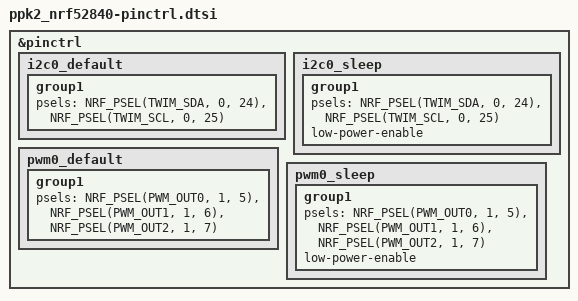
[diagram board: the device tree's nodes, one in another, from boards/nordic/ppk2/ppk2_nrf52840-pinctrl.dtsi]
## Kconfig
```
# SPDX-License-Identifier: Apache-2.0

mainmenu "Joule Counter firmware"

menu "PPK2"

config PPK2_USB_VID
	hex "USB vendor ID"
	default 0x1915
	help
	  The desktop Power Profiler app only lists devices carrying Nordic's
	  vendor ID (nrf-device-lib's "nordicUsb" trait).

config PPK2_USB_PID
	hex "USB product ID"
	default 0xC00A
	help
	  The desktop app recognises a PPK2 by idProduct == 0xC00A.

config PPK2_USB_MANUFACTURER
	string "USB manufacturer string"
	default "Nordic Semiconductor"

config PPK2_USB_PRODUCT
	string "USB product string"
	default "Joule Counter"

config PPK2_DFU_SEMVER
	string "Version string served on the DFU trigger interface"
	default "joule_counter 0.1.0"
	help
	  The app reads this string to decide whether it should offer to
	  reprogram the kit. This firmware's wire protocol has diverged from
	  the stock PPK2's (voltage stream, wider samples), so it identifies as
	  its own product rather than claiming to be a power_profiler_kit_2.
	  The default matches what Joule-Counter's DeviceSelector expects, so
	  the app leaves this firmware alone.

config PPK2_FW_VERSION_MAJOR
	int "Firmware major version reported in DFU info"
	default 1

config PPK2_FW_VERSION_MINOR
	int "Firmware minor version reported in DFU info"
	default 2

config PPK2_DEFAULT_VDD_MV
	int "Source-mode output voltage used when the EEPROM holds none (mV)"
	range 800 5000
	default 3000

config PPK2_DISCARD_SWITCH_SAMPLES
	bool "Drop samples taken while the range switches are in transition"
	default y
	help
	  The analog front end reports an inconsistent switch pattern for a few
	  microseconds while it changes range. Such samples carry no usable
	  current reading; dropping them keeps the sample counter contiguous so
	  the desktop app never sees them.

config PPK2_SAMPLE_RING_SAMPLES
	int "Sample ring buffer depth (samples, power of two)"
	default 4096
	help
	  Eight 512-sample blocks by default: enough to ride out USB scheduling
	  jitter without dropping data. 16 KiB of RAM.

config PPK2_USB_TX_INFLIGHT
	int "Sample blocks queued to the USB controller at once"
	range 1 8
	default 4

config PPK2_STREAM_KEEPS_CPU_AWAKE
	bool "Skip WFI in the idle thread while the current stream runs"
	default y
	select ARM_ON_ENTER_CPU_IDLE_HOOK
	help
	  Waking the CPU from WFI takes about 12.5 us on this kit, longer than
	  the 10 us sample period, so an idle CPU services only every other
	  conversion. With this enabled the idle thread spins instead of
	  sleeping while sampling is active. The kit is USB powered and its own
	  consumption is not what it measures, so nothing is lost.

endmenu

source "Kconfig.zephyr"
```

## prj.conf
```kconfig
# Power Profiler Kit II firmware.
#
# The board supplies the LFCLK source, the bootloader-aware flash offset and
# the USB stack selection; this file asks for what the application uses.

CONFIG_LOG=y
CONFIG_LOG_DEFAULT_LEVEL=3

# Cortex-M4F: calibration maths and voltage conversion are floating point.
CONFIG_FPU=y

# The SAADC END handler runs as a zero-latency interrupt: it has 10 us to
# collect each result and must not wait behind irq_lock() sections in the USB
# driver. It makes no kernel calls; a TIMER3 compare interrupt signals blocks.
CONFIG_ZERO_LATENCY_IRQS=y

CONFIG_GPIO=y
CONFIG_I2C=y
CONFIG_EEPROM=y
CONFIG_PWM=y
CONFIG_LED=y
CONFIG_LED_PWM=y
CONFIG_HWINFO=y
CONFIG_REBOOT=y
CONFIG_CRC=y

# The metadata reply and the shell print floats with printf-style formatting.
CONFIG_PICOLIBC_IO_FLOAT=y
CONFIG_CBPRINTF_FP_SUPPORT=y

# USB: this application builds its own composite device (data port, shell
# port, DFU trigger), so the board's boot-time CDC ACM convenience must stay
# out of the way.
CONFIG_USB_DEVICE_STACK_NEXT=y
CONFIG_USBD_CDC_ACM_CLASS=y
CONFIG_CDC_ACM_SERIAL_INITIALIZE_AT_BOOT=n
# Sample blocks are 4 KiB bulk transfers (512 two-word samples); several are
# in flight at once and the pool needs headroom beyond them for headers and
# the control/RX buffers, or allocations fail under load.
CONFIG_UDC_BUF_POOL_SIZE=32768
CONFIG_UDC_BUF_COUNT=32

CONFIG_SERIAL=y
CONFIG_CONSOLE=y
CONFIG_UART_CONSOLE=y
CONFIG_UART_LINE_CTRL=y
CONFIG_SHELL=y
CONFIG_SHELL_BACKEND_SERIAL=y
CONFIG_SHELL_BACKEND_SERIAL_CHECK_DTR=y
CONFIG_SHELL_PROMPT_UART="ppk2:~$ "

CONFIG_MAIN_STACK_SIZE=4096
CONFIG_SYSTEM_WORKQUEUE_STACK_SIZE=2048
CONFIG_HEAP_MEM_POOL_SIZE=8192
```

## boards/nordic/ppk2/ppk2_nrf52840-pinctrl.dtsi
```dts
/*
 * SPDX-License-Identifier: Apache-2.0
 */

&pinctrl {
	/* U7 (24CW160 EEPROM) and U10 (MCP4451 quad digital potentiometer)
	 * share this bus.
	 */
	i2c0_default: i2c0_default {
		group1 {
			psels = <NRF_PSEL(TWIM_SDA, 0, 24)>,
				<NRF_PSEL(TWIM_SCL, 0, 25)>;
		};
	};

	i2c0_sleep: i2c0_sleep {
		group1 {
			psels = <NRF_PSEL(TWIM_SDA, 0, 24)>,
				<NRF_PSEL(TWIM_SCL, 0, 25)>;
			low-power-enable;
		};
	};

	/* Status LED channels, through the Q15/Q1 low-side MOSFETs. */
	pwm0_default: pwm0_default {
		group1 {
			psels = <NRF_PSEL(PWM_OUT0, 1, 5)>,
				<NRF_PSEL(PWM_OUT1, 1, 6)>,
				<NRF_PSEL(PWM_OUT2, 1, 7)>;
		};
	};

	pwm0_sleep: pwm0_sleep {
		group1 {
			psels = <NRF_PSEL(PWM_OUT0, 1, 5)>,
				<NRF_PSEL(PWM_OUT1, 1, 6)>,
				<NRF_PSEL(PWM_OUT2, 1, 7)>;
			low-power-enable;
		};
	};
};
```

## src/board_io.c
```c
/*
 * Control and status lines of the PPK2 front end.
 *
 * SPDX-License-Identifier: Apache-2.0
 */

#include <zephyr/kernel.h>
#include <zephyr/device.h>
#include <zephyr/devicetree.h>
#include <zephyr/drivers/gpio.h>
#include <zephyr/logging/log.h>

#include "board_io.h"
#include "ppk2.h"

LOG_MODULE_REGISTER(board_io, CONFIG_LOG_DEFAULT_LEVEL);

#define CTRL_NODE DT_NODELABEL(ppk2_control)

static const struct gpio_dt_spec ctrl[BOARD_CTRL_COUNT] = {
	[BOARD_CTRL_VOUT_EN] = GPIO_DT_SPEC_GET(CTRL_NODE, vout_en_gpios),
	[BOARD_CTRL_VLDO_EN] = GPIO_DT_SPEC_GET(CTRL_NODE, vldo_en_gpios),
	[BOARD_CTRL_VEXT_EN] = GPIO_DT_SPEC_GET(CTRL_NODE, vext_en_gpios),
	[BOARD_CTRL_REG_EN] = GPIO_DT_SPEC_GET(CTRL_NODE, reg_en_gpios),
	[BOARD_CTRL_ANA_EN] = GPIO_DT_SPEC_GET(CTRL_NODE, ana_en_gpios),
	[BOARD_CTRL_LP_EN] = GPIO_DT_SPEC_GET(CTRL_NODE, lp_en_gpios),
};

static const struct gpio_dt_spec cal[BOARD_CAL_COUNT] = {
	GPIO_DT_SPEC_GET_BY_IDX(CTRL_NODE, cal_gpios, 0),
	GPIO_DT_SPEC_GET_BY_IDX(CTRL_NODE, cal_gpios, 1),
	GPIO_DT_SPEC_GET_BY_IDX(CTRL_NODE, cal_gpios, 2),
	GPIO_DT_SPEC_GET_BY_IDX(CTRL_NODE, cal_gpios, 3),
};

static const struct gpio_dt_spec sw[4] = {
	GPIO_DT_SPEC_GET_BY_IDX(CTRL_NODE, sw_gpios, 0),
	GPIO_DT_SPEC_GET_BY_IDX(CTRL_NODE, sw_gpios, 1),
	GPIO_DT_SPEC_GET_BY_IDX(CTRL_NODE, sw_gpios, 2),
	GPIO_DT_SPEC_GET_BY_IDX(CTRL_NODE, sw_gpios, 3),
};

static const struct gpio_dt_spec lp_data[8] = {
	GPIO_DT_SPEC_GET_BY_IDX(CTRL_NODE, lp_data_gpios, 0),
	GPIO_DT_SPEC_GET_BY_IDX(CTRL_NODE, lp_data_gpios, 1),
	GPIO_DT_SPEC_GET_BY_IDX(CTRL_NODE, lp_data_gpios, 2),
	GPIO_DT_SPEC_GET_BY_IDX(CTRL_NODE, lp_data_gpios, 3),
	GPIO_DT_SPEC_GET_BY_IDX(CTRL_NODE, lp_data_gpios, 4),
	GPIO_DT_SPEC_GET_BY_IDX(CTRL_NODE, lp_data_gpios, 5),
	GPIO_DT_SPEC_GET_BY_IDX(CTRL_NODE, lp_data_gpios, 6),
	GPIO_DT_SPEC_GET_BY_IDX(CTRL_NODE, lp_data_gpios, 7),
};

static const struct gpio_dt_spec ext_usb = GPIO_DT_SPEC_GET(CTRL_NODE, ext_usb_gpios);

/*
 * The sampling interrupt reads GPIO port registers directly rather than
 * going through the driver, so the pin numbers it assumes are pinned to the
 * devicetree here.
 */
BUILD_ASSERT(DT_GPIO_PIN_BY_IDX(CTRL_NODE, sw_gpios, 0) == 0);
BUILD_ASSERT(DT_GPIO_PIN_BY_IDX(CTRL_NODE, sw_gpios, 1) == 1);
BUILD_ASSERT(DT_GPIO_PIN_BY_IDX(CTRL_NODE, sw_gpios, 2) == 26);
BUILD_ASSERT(DT_GPIO_PIN_BY_IDX(CTRL_NODE, sw_gpios, 3) == 27);
BUILD_ASSERT(DT_GPIO_PIN_BY_IDX(CTRL_NODE, lp_data_gpios, 0) == BOARD_P0_LOGIC_SHIFT);
BUILD_ASSERT(DT_GPIO_PIN_BY_IDX(CTRL_NODE, lp_data_gpios, 7) == BOARD_P0_LOGIC_SHIFT + 7);
BUILD_ASSERT(DT_GPIO_PIN(CTRL_NODE, ext_usb_gpios) == BOARD_P1_EXT_USB_PIN);

/*
 * The comparators close the bypass switches in order as the current rises:
 * SW1 first, then SW2 on top of it, and so on. Any other pattern is a
 * snapshot taken mid-transition.
 */
static const uint8_t range_lut[16] = {
	[0x0] = 0, [0x1] = 1, [0x3] = 2, [0x7] = 3, [0xF] = 4,
	[0x2] = PPK2_RANGE_SWITCHING, [0x4] = PPK2_RANGE_SWITCHING,
	[0x5] = PPK2_RANGE_SWITCHING, [0x6] = PPK2_RANGE_SWITCHING,
	[0x8] = PPK2_RANGE_SWITCHING, [0x9] = PPK2_RANGE_SWITCHING,
	[0xA] = PPK2_RANGE_SWITCHING, [0xB] = PPK2_RANGE_SWITCHING,
	[0xC] = PPK2_RANGE_SWITCHING, [0xD] = PPK2_RANGE_SWITCHING,
	[0xE] = PPK2_RANGE_SWITCHING,
};

static int configure_all(const struct gpio_dt_spec *specs, size_t n, gpio_flags_t flags)
{
	for (size_t i = 0; i < n; i++) {
		if (!gpio_is_ready_dt(&specs[i])) {
			return -ENODEV;
		}

		int ret = gpio_pin_configure_dt(&specs[i], flags);

		if (ret < 0) {
			return ret;
		}
	}

	return 0;
}

int board_io_init(void)
{
	int ret;

	/* Everything that can put voltage on the terminals starts off. */
	ret = configure_all(ctrl, ARRAY_SIZE(ctrl), GPIO_OUTPUT_INACTIVE);
	if (ret < 0) {
		LOG_ERR("control lines: %d", ret);
		return ret;
	}

	ret = configure_all(cal, ARRAY_SIZE(cal), GPIO_OUTPUT_INACTIVE);
	if (ret < 0) {
		LOG_ERR("calibration loads: %d", ret);
		return ret;
	}

	ret = configure_all(sw, ARRAY_SIZE(sw), GPIO_INPUT);
	if (ret < 0) {
		LOG_ERR("range inputs: %d", ret);
		return ret;
	}

	ret = configure_all(lp_data, ARRAY_SIZE(lp_data), GPIO_INPUT);
	if (ret < 0) {
		LOG_ERR("logic port: %d", ret);
		return ret;
	}

	ret = gpio_pin_configure_dt(&ext_usb, GPIO_INPUT);
	if (ret < 0) {
		return ret;
	}

	/* The analog rails and the logic-port translator are always wanted. */
	board_io_set(BOARD_CTRL_ANA_EN, true);
	board_io_set(BOARD_CTRL_LP_EN, true);

	return 0;
}

int board_io_set(enum board_ctrl line, bool on)
{
	if (line >= BOARD_CTRL_COUNT) {
		return -EINVAL;
	}

	return gpio_pin_set_dt(&ctrl[line], on ? 1 : 0);
}

bool board_io_get(enum board_ctrl line)
{
	if (line >= BOARD_CTRL_COUNT) {
		return false;
	}

	return gpio_pin_get_dt(&ctrl[line]) > 0;
}

int board_io_set_cal_load(enum board_cal_load load)
{
	/* Never two loads at once: open the active one before closing another. */
	for (int i = 0; i < BOARD_CAL_COUNT; i++) {
		if (i != load) {
			gpio_pin_set_dt(&cal[i], 0);
		}
	}

	if (load >= 0 && load < BOARD_CAL_COUNT) {
		return gpio_pin_set_dt(&cal[load], 1);
	}

	return 0;
}

uint8_t board_io_decode_range(uint32_t sw_bits)
{
	return range_lut[sw_bits & 0xF];
}

uint8_t board_io_read_range(void)
{
	uint32_t bits = 0;

	for (int i = 0; i < 4; i++) {
		if (gpio_pin_get_dt(&sw[i]) > 0) {
			bits |= BIT(i);
		}
	}

	return board_io_decode_range(bits);
}

bool board_io_ext_usb_present(void)
{
	return gpio_pin_get_dt(&ext_usb) > 0;
}
```

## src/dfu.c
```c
/*
 * Hand-over to the factory nRF5 bootloader.
 *
 * The bootloader starts DFU mode when it finds BOOTLOADER_DFU_START in
 * GPREGRET after a reset. That is also what the desktop app's firmware update
 * relies on, through the DFU trigger USB interface.
 *
 * SPDX-License-Identifier: Apache-2.0
 */

#include <zephyr/kernel.h>
#include <zephyr/sys/reboot.h>
#include <zephyr/logging/log.h>

#include <nrfx.h>
#include <hal/nrf_power.h>

#include "dfu.h"

LOG_MODULE_REGISTER(dfu, CONFIG_LOG_DEFAULT_LEVEL);

#define BOOTLOADER_DFU_START	0xB1
#define NRF52840_FLASH_SIZE	(1024U * 1024U)
#define NRF52840_FLASH_PAGE	4096U

extern char __rom_region_start[];
/* Exact image size, as the linker computes it; the region end is page-rounded. */
extern char _flash_used[];

static void reboot_work_handler(struct k_work *work)
{
	ARG_UNUSED(work);

	nrf_power_gpregret_set(NRF_POWER, 0, BOOTLOADER_DFU_START);
	sys_reboot(SYS_REBOOT_COLD);
}

static K_WORK_DELAYABLE_DEFINE(reboot_work, reboot_work_handler);

void dfu_get_info(struct dfu_info *info)
{
	info->address = (uint32_t)__rom_region_start;
	info->firmware_size = (uint32_t)_flash_used;
	info->version_major = CONFIG_PPK2_FW_VERSION_MAJOR;
	info->version_minor = CONFIG_PPK2_FW_VERSION_MINOR;
	info->firmware_id = 0;
	info->flash_size = NRF52840_FLASH_SIZE;
	info->flash_page_size = NRF52840_FLASH_PAGE;
}

void dfu_enter_bootloader(void)
{
	LOG_INF("rebooting into bootloader");
	k_work_schedule(&reboot_work, K_MSEC(100));
}
```

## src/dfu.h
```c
/*
 * Hand-over to the factory nRF5 bootloader.
 *
 * SPDX-License-Identifier: Apache-2.0
 */

#ifndef DFU_H_
#define DFU_H_

#include <stdint.h>

/* Layout of the reply to the DFU trigger's DFU_INFO request. */
struct dfu_info {
	uint32_t address;
	uint32_t firmware_size;
	uint16_t version_major;
	uint16_t version_minor;
	uint32_t firmware_id;
	uint32_t flash_size;
	uint32_t flash_page_size;
} __packed;

void dfu_get_info(struct dfu_info *info);

/* Reboots into the bootloader after a short delay so USB can finish up. */
void dfu_enter_bootloader(void);

#endif /* DFU_H_ */
```

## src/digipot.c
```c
/*
 * MCP4451 quad digital potentiometer (U10).
 *
 * SPDX-License-Identifier: Apache-2.0
 */

#include <zephyr/kernel.h>
#include <zephyr/drivers/i2c.h>
#include <zephyr/logging/log.h>

#include "digipot.h"

LOG_MODULE_REGISTER(digipot, CONFIG_LOG_DEFAULT_LEVEL);

static const struct i2c_dt_spec pot = I2C_DT_SPEC_GET(DT_NODELABEL(digipot));

/* Volatile wiper register addresses, MCP4451 datasheet table 4-1. */
static const uint8_t wiper_reg[4] = { 0x00, 0x01, 0x06, 0x07 };

static uint16_t last_code[4];

int digipot_init(void)
{
	if (!i2c_is_ready_dt(&pot)) {
		LOG_ERR("I2C bus not ready");
		return -ENODEV;
	}

	return 0;
}

int digipot_set(enum digipot_wiper wiper, uint16_t code)
{
	if (wiper > DIGIPOT_IA_OFFSET) {
		return -EINVAL;
	}

	if (code > DIGIPOT_CODE_MAX) {
		code = DIGIPOT_CODE_MAX;
	}

	/* Command byte: AD3..AD0, C1 C0 = 00 (write), D9 D8. Then D7..D0. */
	const uint8_t buf[2] = {
		(uint8_t)((wiper_reg[wiper] << 4) | ((code >> 8) & 0x03)),
		(uint8_t)(code & 0xFF),
	};

	int ret = i2c_write_dt(&pot, buf, sizeof(buf));

	if (ret == 0) {
		last_code[wiper] = code;
	} else {
		LOG_WRN("wiper %d write failed: %d", wiper, ret);
	}

	return ret;
}

uint16_t digipot_get(enum digipot_wiper wiper)
{
	return wiper <= DIGIPOT_IA_OFFSET ? last_code[wiper] : 0;
}
```

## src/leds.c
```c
/*
 * Status LED patterns.
 *
 *   blue, breathing   no host connected
 *   blue, steady      host connected, idle
 *   green, breathing  streaming samples
 *   red added         DUT output is powered
 *
 * SPDX-License-Identifier: Apache-2.0
 */

#include <zephyr/kernel.h>
#include <zephyr/device.h>
#include <zephyr/drivers/led.h>
#include <zephyr/logging/log.h>

#include "leds.h"
#include "power.h"
#include "protocol.h"
#include "usb_ppk.h"

LOG_MODULE_REGISTER(leds, CONFIG_LOG_DEFAULT_LEVEL);

#define LED_RED		0
#define LED_GREEN	1
#define LED_BLUE	2

#define TICK_MS		40
#define BREATH_STEPS	50

static const struct device *const leds = DEVICE_DT_GET(DT_NODELABEL(pwmleds));
static bool ready;

static uint8_t breathe(uint32_t tick, uint8_t low, uint8_t high)
{
	uint32_t phase = tick % (2 * BREATH_STEPS);
	uint32_t up = phase < BREATH_STEPS ? phase : (2 * BREATH_STEPS - phase);

	return low + (uint8_t)((high - low) * up / BREATH_STEPS);
}

static void set_rgb(uint8_t r, uint8_t g, uint8_t b)
{
	led_set_brightness(leds, LED_RED, r);
	led_set_brightness(leds, LED_GREEN, g);
	led_set_brightness(leds, LED_BLUE, b);
}

static void led_thread(void *p1, void *p2, void *p3)
{
	uint32_t tick = 0;

	ARG_UNUSED(p1);
	ARG_UNUSED(p2);
	ARG_UNUSED(p3);

	while (!ready) {
		k_msleep(TICK_MS);
	}

	for (;;) {
		uint8_t r = power_output() ? 25 : 0;
		uint8_t g = 0;
		uint8_t b = 0;

		if (protocol_streaming()) {
			g = breathe(tick, 5, 60);
		} else if (usb_ppk_data_connected()) {
			b = 30;
		} else {
			b = breathe(tick, 2, 25);
		}

		set_rgb(r, g, b);
		tick++;
		k_msleep(TICK_MS);
	}
}

K_THREAD_DEFINE(leds_tid, 1024, led_thread, NULL, NULL, NULL, K_PRIO_PREEMPT(14), 0, 0);

int leds_init(void)
{
	if (!device_is_ready(leds)) {
		LOG_ERR("PWM LEDs not ready");
		return -ENODEV;
	}

	set_rgb(20, 20, 20);
	ready = true;

	return 0;
}
```

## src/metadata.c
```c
/*
 * Calibration metadata stored in the on-board EEPROM (U7).
 *
 * The EEPROM is the one copy of this unit's factory calibration, so writes
 * are field-wise, to offsets confirmed against the stock layout, and only
 * for values this firmware actually changes. Everything else in the stock
 * image is read and left alone.
 *
 * SPDX-License-Identifier: Apache-2.0
 */

#include <ctype.h>
#include <math.h>
#include <stdio.h>
#include <stdlib.h>
#include <string.h>

#include <zephyr/kernel.h>
#include <zephyr/device.h>
#include <zephyr/drivers/eeprom.h>
#include <zephyr/sys/byteorder.h>
#include <zephyr/sys/crc.h>
#include <zephyr/logging/log.h>

#include <nrfx.h>

#include "metadata.h"
#include "ppk2.h"
#include "sampling.h"

LOG_MODULE_REGISTER(metadata, CONFIG_LOG_DEFAULT_LEVEL);

/*
 * Our own backup lives clear of both stock regions: its primary image ends at
 * 0x100 and its backup copy (with a trailing CRC) occupies 0x600..0x702.
 */
#define BACKUP_OFFSET		0x200
#define BACKUP_MAGIC		0x324B5050	/* "PPK2" */
#define SAVE_DEBOUNCE		K_SECONDS(2)

#define IA_DEFAULT		128
#define IA_MAX			256

/*
 * Stock masks the range-0 gain terms when it reports them, whatever the
 * EEPROM holds (a real unit stored GS0 = -1138.7, GI0 = 1.03 and reported
 * 1e-19 and 1.0). The epsilon rather than zero matters: the desktop app
 * substitutes its own default of 1.0 for any value that parses as zero.
 */
#define REPORTED_GS0		1e-19f
#define REPORTED_GI0		1.0f

struct backup_image {
	uint32_t magic;
	struct ppk2_metadata meta;
	uint32_t crc;
} __packed;

static const struct device *const eeprom = DEVICE_DT_GET(DT_ALIAS(eeprom_0));

static struct ppk2_metadata meta;
/* What the EEPROM holds for the fields we own, so saves touch only changes. */
static struct ppk2_metadata stored;
static bool calibrated;
static bool ia_unknown;
static K_MUTEX_DEFINE(lock);

/*
 * Mirrors the desktop app's own fallbacks, which it substitutes for any key
 * that parses as zero. Sending anything else for an uncalibrated kit would
 * therefore be overridden anyway.
 */
static const struct ppk2_metadata defaults = {
	.r = { 1031.64f, 101.65f, 10.15f, 0.94f, 0.043f },
	.gs = { 1.0f, 1.0f, 1.0f, 1.0f, 1.0f },
	.gi = { 1.0f, 1.0f, 1.0f, 1.0f, 1.0f },
	.ug = { 1.0f, 1.0f, 1.0f, 1.0f, 1.0f },
	.vdd = CONFIG_PPK2_DEFAULT_VDD_MV,
	.mode = PPK2_MODE_AMPERE,
	.calibrated = 0,
	.ia = IA_DEFAULT,
};

static uint16_t derived_hw(void)
{
	/* Stock reports the low 16 bits of DEVICEID[0] as a decimal integer;
	 * a real unit confirmed the field and its width.
	 */
	return (uint16_t)(NRF_FICR->DEVICEID[0] & 0xFFFFU);
}

static bool all_finite(const float *v, size_t n)
{
	for (size_t k = 0; k < n; k++) {
		if (!isfinite(v[k])) {
			return false;
		}
	}

	return true;
}

static bool resistances_plausible(const float *r)
{
	for (size_t k = 0; k < PPK2_RANGE_COUNT; k++) {
		if (!isfinite(r[k]) || r[k] <= 0.001f || r[k] > 100000.0f) {
			return false;
		}
	}

	return true;
}

static void decode_image(const uint8_t *img, struct ppk2_metadata *m)
{
	memcpy(m->r, &img[EEPROM_OFF_R], sizeof(m->r));
	memcpy(m->gs, &img[EEPROM_OFF_GS], sizeof(m->gs));
	memcpy(m->o, &img[EEPROM_OFF_O], sizeof(m->o));
	memcpy(m->s, &img[EEPROM_OFF_S], sizeof(m->s));
	memcpy(m->i, &img[EEPROM_OFF_I], sizeof(m->i));
	memcpy(m->gi, &img[EEPROM_OFF_GI], sizeof(m->gi));
	memcpy(m->ug, &img[EEPROM_OFF_UG], sizeof(m->ug));
	m->vdd = sys_get_le16(&img[EEPROM_OFF_VDD]);
	m->mode = img[EEPROM_OFF_MODE];
	m->calibrated = img[EEPROM_OFF_CALIBRATED];
	m->ia = sys_get_le16(&img[EEPROM_OFF_IA]);
	m->hw = derived_hw();
}

static void sanitize(struct ppk2_metadata *m)
{
	if (!all_finite(m->gs, PPK2_RANGE_COUNT)) {
		memcpy(m->gs, defaults.gs, sizeof(m->gs));
	}
	if (!all_finite(m->gi, PPK2_RANGE_COUNT)) {
		memcpy(m->gi, defaults.gi, sizeof(m->gi));
	}
	if (!all_finite(m->o, PPK2_RANGE_COUNT)) {
		memset(m->o, 0, sizeof(m->o));
	}
	if (!all_finite(m->s, PPK2_RANGE_COUNT)) {
		memset(m->s, 0, sizeof(m->s));
	}
	if (!all_finite(m->i, PPK2_RANGE_COUNT)) {
		memset(m->i, 0, sizeof(m->i));
	}
	if (!all_finite(m->ug, PPK2_RANGE_COUNT)) {
		memcpy(m->ug, defaults.ug, sizeof(m->ug));
	}
	for (size_t k = 0; k < PPK2_RANGE_COUNT; k++) {
		if (m->ug[k] <= 0.0f || m->ug[k] > 10.0f) {
			m->ug[k] = 1.0f;
		}
	}

	if (m->vdd < 800 || m->vdd > 5000) {
		m->vdd = CONFIG_PPK2_DEFAULT_VDD_MV;
	}
	if (m->mode != PPK2_MODE_AMPERE && m->mode != PPK2_MODE_SOURCE) {
		m->mode = PPK2_MODE_AMPERE;
	}
	if (m->calibrated > 1) {
		m->calibrated = 0;
	}

	/* Fresh EEPROM reads 0xFFFF here, and the one real unit seen so far
	 * held a value far beyond the wiper's range in its stock backup.
	 */
	ia_unknown = m->ia > IA_MAX;
	if (ia_unknown) {
		LOG_WRN("no usable IA wiper value in EEPROM (%u), will trim", m->ia);
		m->ia = IA_DEFAULT;
	}
}

void metadata_load_defaults(void)
{
	k_mutex_lock(&lock, K_FOREVER);
	meta = defaults;
	meta.hw = derived_hw();
	calibrated = false;
	ia_unknown = true;
	k_mutex_unlock(&lock);
}

int metadata_init(void)
{
	uint8_t img[EEPROM_STOCK_IMAGE_SIZE];
	int ret;

	if (!device_is_ready(eeprom)) {
		LOG_ERR("EEPROM not ready");
		metadata_load_defaults();
		return -ENODEV;
	}

	ret = eeprom_read(eeprom, 0, img, sizeof(img));
	if (ret < 0) {
		LOG_ERR("EEPROM read failed: %d", ret);
		metadata_load_defaults();
		return ret;
	}

	k_mutex_lock(&lock, K_FOREVER);
	decode_image(img, &meta);
	stored = meta;

	if (resistances_plausible(meta.r)) {
		calibrated = true;
		sanitize(&meta);
		LOG_INF("calibration loaded: R0=%.2f R4=%.4f vdd=%u mode=%u ia=%u flag=%u",
			(double)meta.r[0], (double)meta.r[4], meta.vdd, meta.mode, meta.ia,
			meta.calibrated);
	} else {
		LOG_WRN("EEPROM holds no usable calibration, using defaults");
		meta = defaults;
		meta.hw = derived_hw();
		calibrated = false;
		ia_unknown = true;
	}
	k_mutex_unlock(&lock);

	return 0;
}

struct ppk2_metadata *metadata_get(void)
{
	return &meta;
}

bool metadata_is_calibrated(void)
{
	return calibrated;
}

bool metadata_ia_unknown(void)
{
	return ia_unknown;
}

static int write_if_changed(size_t offset, const void *now, void *was, size_t len)
{
	if (memcmp(now, was, len) == 0) {
		return 0;
	}

	int ret = eeprom_write(eeprom, offset, now, len);

	if (ret == 0) {
		memcpy(was, now, len);
	} else {
		LOG_ERR("EEPROM write at %u failed: %d", (unsigned int)offset, ret);
	}

	return ret;
}

int metadata_save(void)
{
	struct ppk2_metadata m;
	uint8_t le16[2];
	int ret;

	if (!device_is_ready(eeprom)) {
		return -ENODEV;
	}

	k_mutex_lock(&lock, K_FOREVER);
	m = meta;

	sys_put_le16(m.vdd, le16);
	ret = write_if_changed(EEPROM_OFF_VDD, le16, &stored.vdd, sizeof(le16));
	stored.vdd = m.vdd;

	if (ret == 0) {
		ret = write_if_changed(EEPROM_OFF_UG, m.ug, stored.ug, sizeof(m.ug));
	}
	if (ret == 0) {
		ret = write_if_changed(EEPROM_OFF_MODE, &m.mode, &stored.mode, sizeof(m.mode));
	}
	if (ret == 0) {
		sys_put_le16(m.ia, le16);
		ret = write_if_changed(EEPROM_OFF_IA, le16, &stored.ia, sizeof(le16));
		stored.ia = m.ia;
	}
	k_mutex_unlock(&lock);

	return ret;
}

static void save_work_handler(struct k_work *work)
{
	ARG_UNUSED(work);
	metadata_save();
}

static K_WORK_DELAYABLE_DEFINE(save_work, save_work_handler);

void metadata_save_deferred(void)
{
	k_work_reschedule(&save_work, SAVE_DEBOUNCE);
}

int metadata_backup_write(void)
{
	struct backup_image img;

	if (!device_is_ready(eeprom)) {
		return -ENODEV;
	}

	k_mutex_lock(&lock, K_FOREVER);
	img.magic = BACKUP_MAGIC;
	img.meta = meta;
	k_mutex_unlock(&lock);
	img.crc = crc32_ieee((const uint8_t *)&img.meta, sizeof(img.meta));

	return eeprom_write(eeprom, BACKUP_OFFSET, &img, sizeof(img));
}

static int backup_read(struct backup_image *img)
{
	int ret;

	if (!device_is_ready(eeprom)) {
		return -ENODEV;
	}

	ret = eeprom_read(eeprom, BACKUP_OFFSET, img, sizeof(*img));
	if (ret < 0) {
		return ret;
	}

	if (img->magic != BACKUP_MAGIC ||
	    img->crc != crc32_ieee((const uint8_t *)&img->meta, sizeof(img->meta))) {
		return -EBADMSG;
	}

	return 0;
}

int metadata_backup_valid(void)
{
	struct backup_image img;

	return backup_read(&img);
}

/*
 * Restores only what this firmware owns. The factory constants are not
 * rewritten from our backup: if they were lost, stock's own backup copy at
 * 0x600 is the authoritative source, not ours.
 */
int metadata_backup_restore(void)
{
	struct backup_image img;
	int ret = backup_read(&img);

	if (ret < 0) {
		return ret;
	}

	k_mutex_lock(&lock, K_FOREVER);
	memcpy(meta.ug, img.meta.ug, sizeof(meta.ug));
	meta.vdd = img.meta.vdd;
	meta.mode = img.meta.mode;
	meta.ia = img.meta.ia;
	k_mutex_unlock(&lock);

	return metadata_save();
}

/*
 * The desktop app lower-cases this text, turns every "key: value" line into a
 * JSON member and parses the result, so the values must be plain numbers:
 * never NaN or infinity.
 */
size_t metadata_format(char *buf, size_t size)
{
	struct ppk2_metadata m;
	size_t pos = 0;

	k_mutex_lock(&lock, K_FOREVER);
	m = meta;
	k_mutex_unlock(&lock);

	m.gs[0] = REPORTED_GS0;
	m.gi[0] = REPORTED_GI0;

#define PUT(...)								\
	do {									\
		int n_ = snprintf(buf + pos, size - pos, __VA_ARGS__);		\
		if (n_ < 0 || (size_t)n_ >= size - pos) {			\
			return 0;						\
		}								\
		pos += (size_t)n_;						\
	} while (0)

	PUT("Calibrated: %u\n", m.calibrated);
	for (int k = 0; k < PPK2_RANGE_COUNT; k++) {
		PUT("R%d: %.20f\n", k, (double)m.r[k]);
	}
	for (int k = 0; k < PPK2_RANGE_COUNT; k++) {
		PUT("GS%d: %.20f\n", k, (double)m.gs[k]);
	}
	for (int k = 0; k < PPK2_RANGE_COUNT; k++) {
		PUT("GI%d: %.20f\n", k, (double)m.gi[k]);
	}
	for (int k = 0; k < PPK2_RANGE_COUNT; k++) {
		PUT("O%d: %.20f\n", k, (double)m.o[k]);
	}
	PUT("VDD: %u\n", m.vdd);
	PUT("HW: %u\n", m.hw);
	PUT("mode: %u\n", m.mode);
	for (int k = 0; k < PPK2_RANGE_COUNT; k++) {
		PUT("S%d: %.20f\n", k, (double)m.s[k]);
	}
	for (int k = 0; k < PPK2_RANGE_COUNT; k++) {
		PUT("I%d: %.20f\n", k, (double)m.i[k]);
	}
	for (int k = 0; k < PPK2_RANGE_COUNT; k++) {
		PUT("UG%d: %.20f\n", k, (double)m.ug[k]);
	}
	PUT("IA: %u\n", m.ia);

	/* Joule Counter additions: how to read the stream's voltage word, and
	 * the sample rate, so the host carries no copy of either.
	 */
	float vfs, vdiv;

	sampling_voltage_scale(&vfs, &vdiv);
	PUT("VFS: %.1f\n", (double)vfs);
	PUT("VDIV: %.3f\n", (double)vdiv);
	PUT("SampleRate: %u\n", PPK2_SAMPLE_RATE_HZ);
	PUT("END\n");
#undef PUT

	return pos;
}

static float *float_array(struct ppk2_metadata *m, const char *name)
{
	if (strcmp(name, "r") == 0) {
		return m->r;
	}
	if (strcmp(name, "gs") == 0) {
		return m->gs;
	}
	if (strcmp(name, "gi") == 0) {
		return m->gi;
	}
	if (strcmp(name, "o") == 0) {
		return m->o;
	}
	if (strcmp(name, "s") == 0) {
		return m->s;
	}
	if (strcmp(name, "i") == 0) {
		return m->i;
	}
	if (strcmp(name, "ug") == 0) {
		return m->ug;
	}

	return NULL;
}

/*
 * Edits the in-RAM copy only. Factory constants (r, gs, gi, o, s, i) can be
 * edited here for experiments but are never persisted by metadata_save().
 */
int metadata_set(const char *key, const char *value)
{
	char name[8];
	size_t n = 0;
	int ret = 0;

	while (key[n] != '\0' && !isdigit((unsigned char)key[n]) && n < sizeof(name) - 1) {
		name[n] = (char)tolower((unsigned char)key[n]);
		n++;
	}
	name[n] = '\0';

	k_mutex_lock(&lock, K_FOREVER);

	if (key[n] != '\0') {
		float *arr = float_array(&meta, name);
		int idx = atoi(&key[n]);

		if (arr == NULL || idx < 0 || idx >= PPK2_RANGE_COUNT) {
			ret = -EINVAL;
		} else {
			float v = strtof(value, NULL);

			if (!isfinite(v)) {
				ret = -EINVAL;
			} else {
				arr[idx] = v;
				if (arr == meta.r) {
					calibrated = resistances_plausible(meta.r);
				}
			}
		}
	} else if (strcmp(name, "vdd") == 0) {
		meta.vdd = (uint16_t)strtoul(value, NULL, 0);
	} else if (strcmp(name, "mode") == 0) {
		meta.mode = (uint8_t)strtoul(value, NULL, 0);
	} else if (strcmp(name, "ia") == 0) {
		meta.ia = (uint16_t)strtoul(value, NULL, 0);
		ia_unknown = false;
	} else {
		ret = -EINVAL;
	}

	k_mutex_unlock(&lock);

	return ret;
}

int metadata_raw_read(size_t offset, uint8_t *buf, size_t len)
{
	if (!device_is_ready(eeprom)) {
		return -ENODEV;
	}

	return eeprom_read(eeprom, offset, buf, len);
}
```

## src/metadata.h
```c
/*
 * Calibration metadata stored in the on-board EEPROM (U7).
 *
 * SPDX-License-Identifier: Apache-2.0
 */

#ifndef METADATA_H_
#define METADATA_H_

#include <stdbool.h>
#include <stddef.h>
#include <stdint.h>

#include "ppk2.h"

/*
 * Byte offsets in the EEPROM, as the stock firmware lays them out. Confirmed
 * against a real unit by diffing its primary image against its stock backup
 * copy, whose VDD, mode and IA the stock firmware reported differently (see
 * calibration/README.md). HW is not stored: stock derives it from the SoC's
 * device ID. Bytes not named here belong to stock and are never written.
 */
#define EEPROM_OFF_R		0	/* float[5] */
#define EEPROM_OFF_GS		20	/* float[5] */
#define EEPROM_OFF_O		40	/* float[5] */
#define EEPROM_OFF_S		60	/* float[5] */
#define EEPROM_OFF_I		80	/* float[5] */
#define EEPROM_OFF_GI		100	/* float[5] */
#define EEPROM_OFF_VDD		120	/* uint16, mV */
#define EEPROM_OFF_UG		128	/* float[5] */
#define EEPROM_OFF_MODE		251	/* uint8 */
#define EEPROM_OFF_CALIBRATED	252	/* uint8; stock's flag, read but never written */
#define EEPROM_OFF_IA		255	/* uint16, unaligned */
#define EEPROM_STOCK_IMAGE_SIZE	257

/* In-RAM view. Not a byte image of the EEPROM; see the offsets above. */
struct ppk2_metadata {
	float r[PPK2_RANGE_COUNT];	/* shunt resistance per range, ohm */
	float gs[PPK2_RANGE_COUNT];	/* gain, quadratic term */
	float o[PPK2_RANGE_COUNT];	/* zero-current ADC reading */
	float s[PPK2_RANGE_COUNT];	/* supply-voltage dependent offset */
	float i[PPK2_RANGE_COUNT];	/* constant offset */
	float gi[PPK2_RANGE_COUNT];	/* gain, linear term */
	float ug[PPK2_RANGE_COUNT];	/* user gains */
	uint16_t vdd;			/* source-mode setpoint, mV */
	uint16_t hw;			/* low 16 bits of the device ID, as stock reports */
	uint8_t mode;			/* enum ppk2_mode */
	uint8_t calibrated;		/* stock's stored flag, informational */
	uint16_t ia;			/* instrumentation amplifier offset wiper */
};

#define METADATA_TEXT_SIZE 2048

int metadata_init(void);

struct ppk2_metadata *metadata_get(void);

/* The stored shunt values are usable, whatever stock's flag byte says. */
bool metadata_is_calibrated(void);

/* True when the IA wiper value had to be invented rather than read. */
bool metadata_ia_unknown(void);

/* Writes the fields this firmware owns (vdd, ug, mode, ia), only if changed. */
int metadata_save(void);
void metadata_save_deferred(void);
void metadata_load_defaults(void);

int metadata_backup_write(void);
int metadata_backup_restore(void);
int metadata_backup_valid(void);

/* Formats the reply to GetMetadata, terminated by "END\n". */
size_t metadata_format(char *buf, size_t size);

/* Sets one field from its text name ("r0", "gs3", "vdd", "mode", ...). */
int metadata_set(const char *key, const char *value);

int metadata_raw_read(size_t offset, uint8_t *buf, size_t len);

#endif /* METADATA_H_ */
```

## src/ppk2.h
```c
/*
 * Definitions shared across the PPK2 firmware.
 *
 * The wire format here is shared with the Joule-Counter desktop app
 * (Joule-Counter/src/device/serialDevice.ts); change both together.
 *
 * SPDX-License-Identifier: Apache-2.0
 */

#ifndef PPK2_H_
#define PPK2_H_

#include <stdint.h>

/*
 * The two-channel scan itself still converts at 100 kHz, but two words per
 * sample is 800 kB/s and a full-speed CDC link on a real host carried about
 * 530 kB/s sustained. 50 kHz is the 400 kB/s the one-word stream already
 * proved, with margin, and doubles the per-scan acquisition budget.
 */
#define PPK2_SAMPLE_RATE_HZ	50000U
#define PPK2_BLOCK_SAMPLES	512U
#define PPK2_RANGE_COUNT	5U

/* Reported in the range field while the switches are between two ranges. */
#define PPK2_RANGE_SWITCHING	7U

/*
 * Each sample is two 32-bit little-endian words: the current word first,
 * then the voltage word, from the same SAADC scan (one END covers both, so
 * the pair is always from the same 10 us-ish instant). This is Joule
 * Counter's own wire format, no longer PPK2 wire-compatible.
 *
 * Current word:
 *   bits  0..13  ADC value. The 14-bit differential SAADC result shifted
 *                right by two, clamped at zero. The app multiplies it back
 *                by four, so the calibration constants in the EEPROM are in
 *                raw 14-bit counts.
 *   bits 14..16  measurement range 0..4, or 7 while switching.
 *   bit  17      auxiliary USB connector (J1) VBUS present.
 *   bits 18..23  six-bit sample counter, contiguous over emitted samples.
 *   bits 24..31  logic port D0..D7.
 *
 * Voltage word:
 *   bits  0..13  ADC value, same convention as the current word (VDUT vs
 *                AGND, uncalibrated linear divider/gain math on the host).
 *   bits 14..31  reserved, always zero.
 */
#define PPK2_WORDS_PER_SAMPLE	2U

#define PPK2_SAMPLE_ADC_MASK	0x3FFFU
#define PPK2_SAMPLE_RANGE_POS	14U
#define PPK2_SAMPLE_EXT_USB_POS	17U
#define PPK2_SAMPLE_COUNTER_POS	18U
#define PPK2_SAMPLE_COUNTER_MASK 0x3FU
#define PPK2_SAMPLE_LOGIC_POS	24U

#define PPK2_VOLTAGE_ADC_MASK	0x3FFFU

enum ppk2_mode {
	PPK2_MODE_AMPERE = 1,
	PPK2_MODE_SOURCE = 2,
};

/* Commands the host may send on the data port, one opcode byte each. */
enum ppk2_cmd {
	PPK2_CMD_TRIGGER_SET		= 0x01,
	PPK2_CMD_AVG_NUM_SET		= 0x02,
	PPK2_CMD_TRIGGER_WINDOW_SET	= 0x03,
	PPK2_CMD_TRIGGER_INTERVAL_SET	= 0x04,
	PPK2_CMD_TRIGGER_SINGLE_SET	= 0x05,
	PPK2_CMD_AVERAGE_START		= 0x06,
	PPK2_CMD_AVERAGE_STOP		= 0x07,
	PPK2_CMD_RANGE_SET		= 0x08,
	PPK2_CMD_LCD_SET		= 0x09,
	PPK2_CMD_TRIGGER_STOP		= 0x0A,
	PPK2_CMD_DEVICE_RUNNING_SET	= 0x0C,
	PPK2_CMD_REGULATOR_SET		= 0x0D,
	PPK2_CMD_SWITCH_POINT_DOWN	= 0x0E,
	PPK2_CMD_SWITCH_POINT_UP	= 0x0F,
	PPK2_CMD_SET_POWER_MODE		= 0x11,
	PPK2_CMD_RES_USER_SET		= 0x12,
	PPK2_CMD_SPIKE_FILTERING_ON	= 0x15,
	PPK2_CMD_SPIKE_FILTERING_OFF	= 0x16,
	PPK2_CMD_GET_METADATA		= 0x19,
	PPK2_CMD_RESET			= 0x20,
	PPK2_CMD_SET_USER_GAINS		= 0x25,
};

#endif /* PPK2_H_ */
```

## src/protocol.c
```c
/*
 * PPK2 host protocol on the USB data port.
 *
 * Commands arrive as an opcode byte followed by a fixed number of argument
 * bytes. Replies are either the metadata text (terminated by "END") or the
 * binary sample stream, never both at once.
 *
 * SPDX-License-Identifier: Apache-2.0
 */

#include <math.h>
#include <string.h>

#include <zephyr/kernel.h>
#include <zephyr/sys/reboot.h>
#include <zephyr/logging/log.h>

#include "metadata.h"
#include "power.h"
#include "ppk2.h"
#include "protocol.h"
#include "sampling.h"
#include "usb_ppk.h"

LOG_MODULE_REGISTER(protocol, CONFIG_LOG_DEFAULT_LEVEL);

#define CMD_MAX_ARGS		5
#define CMD_QUEUE_DEPTH		16
#define CMD_INTERNAL_LINK	0xFE	/* data port connected / disconnected */

#define TX_BLOCK_TIMEOUT	K_MSEC(250)
#define TX_TEXT_TIMEOUT		K_MSEC(500)

struct cmd {
	uint8_t op;
	uint8_t len;
	uint8_t arg[CMD_MAX_ARGS];
};

/* Argument byte count per opcode; -1 marks opcodes this firmware does not know. */
static const int8_t cmd_arg_len[0x26] = {
	[0 ... 0x25] = -1,
	[PPK2_CMD_TRIGGER_SET] = 2,
	[PPK2_CMD_AVG_NUM_SET] = 1,
	[PPK2_CMD_TRIGGER_WINDOW_SET] = 2,
	[PPK2_CMD_TRIGGER_INTERVAL_SET] = 1,
	[PPK2_CMD_TRIGGER_SINGLE_SET] = 0,
	[PPK2_CMD_AVERAGE_START] = 0,
	[PPK2_CMD_AVERAGE_STOP] = 0,
	[PPK2_CMD_RANGE_SET] = 1,
	[PPK2_CMD_LCD_SET] = 1,
	[PPK2_CMD_TRIGGER_STOP] = 0,
	[PPK2_CMD_DEVICE_RUNNING_SET] = 1,
	[PPK2_CMD_REGULATOR_SET] = 2,
	[PPK2_CMD_SWITCH_POINT_DOWN] = 1,
	[PPK2_CMD_SWITCH_POINT_UP] = 1,
	[PPK2_CMD_SET_POWER_MODE] = 1,
	[PPK2_CMD_RES_USER_SET] = 3,
	[PPK2_CMD_SPIKE_FILTERING_ON] = 0,
	[PPK2_CMD_SPIKE_FILTERING_OFF] = 0,
	[PPK2_CMD_GET_METADATA] = 0,
	[PPK2_CMD_RESET] = 0,
	[PPK2_CMD_SET_USER_GAINS] = 5,
};

K_MSGQ_DEFINE(cmd_q, sizeof(struct cmd), CMD_QUEUE_DEPTH, 4);

/* Serialises everything that goes out on the data port. */
static K_MUTEX_DEFINE(tx_lock);

static volatile bool streaming;
static struct protocol_stats stats;

/* Parser state, touched only from the USB receive context. */
static struct cmd partial;
static bool partial_active;

static void rx_handler(const uint8_t *data, size_t len)
{
	for (size_t k = 0; k < len; k++) {
		uint8_t b = data[k];

		if (!partial_active) {
			int8_t n = b < ARRAY_SIZE(cmd_arg_len) ? cmd_arg_len[b] : -1;

			if (n < 0) {
				stats.unknown_bytes++;
				continue;
			}

			partial.op = b;
			partial.len = 0;
			partial_active = true;
			if (n > 0) {
				continue;
			}
		} else {
			partial.arg[partial.len++] = b;
			if (partial.len < cmd_arg_len[partial.op]) {
				continue;
			}
		}

		partial_active = false;
		if (k_msgq_put(&cmd_q, &partial, K_NO_WAIT) != 0) {
			LOG_WRN("command queue full, dropped 0x%02x", partial.op);
		}
	}
}

static void link_handler(bool connected)
{
	struct cmd c = { .op = CMD_INTERNAL_LINK, .len = 1, .arg = { connected } };

	k_msgq_put(&cmd_q, &c, K_NO_WAIT);
}

static void stream_start(void)
{
	if (streaming) {
		return;
	}

	int ret = sampling_start();

	if (ret < 0) {
		LOG_ERR("cannot start sampling: %d", ret);
		return;
	}

	streaming = true;
	LOG_INF("streaming");
}

static void stream_stop(void)
{
	if (!streaming) {
		return;
	}

	streaming = false;
	sampling_stop();
	power_on_stream_stopped();
	LOG_INF("stopped");
}

static void send_text(const char *text, size_t len)
{
	k_mutex_lock(&tx_lock, K_FOREVER);
	while (len > 0) {
		size_t chunk = MIN(len, 1024U);
		int ret = usb_ppk_data_send((const uint8_t *)text, chunk, TX_TEXT_TIMEOUT);

		if (ret != 0) {
			stats.tx_failures++;
			LOG_WRN("metadata send failed: %d", ret);
			break;
		}
		text += chunk;
		len -= chunk;
	}
	k_mutex_unlock(&tx_lock);
}

static void handle_get_metadata(void)
{
	static char text[METADATA_TEXT_SIZE];

	/* The host expects only text until it has seen END. */
	stream_stop();

	size_t len = metadata_format(text, sizeof(text));

	if (len == 0) {
		LOG_ERR("metadata does not fit its buffer");
		return;
	}

	send_text(text, len);
}

static void handle_set_user_gains(const uint8_t *arg)
{
	uint8_t range = arg[0];
	float gain;

	/* The app serialises the gain as a native little-endian float32. */
	memcpy(&gain, &arg[1], sizeof(gain));

	if (range >= PPK2_RANGE_COUNT || !isfinite(gain) || gain <= 0.0f) {
		LOG_WRN("rejected user gain %u", range);
		return;
	}

	metadata_get()->ug[range] = gain;
	metadata_save_deferred();
}

static void dispatch(const struct cmd *c)
{
	stats.commands++;

	switch (c->op) {
	case CMD_INTERNAL_LINK:
		if (!c->arg[0]) {
			/* Host went away: stop streaming. The DUT output is left
			 * as it was; the app turns it off itself on a clean
			 * close, and a USB hiccup should not cut the DUT's power.
			 */
			stream_stop();
		}
		break;

	case PPK2_CMD_AVERAGE_START:
		stream_start();
		break;

	case PPK2_CMD_AVERAGE_STOP:
		stream_stop();
		break;

	case PPK2_CMD_DEVICE_RUNNING_SET:
		power_set_output(c->arg[0] != 0);
		break;

	case PPK2_CMD_REGULATOR_SET:
		power_set_vdd((uint16_t)((c->arg[0] << 8) | c->arg[1]));
		break;

	case PPK2_CMD_SET_POWER_MODE:
		power_set_mode(c->arg[0]);
		break;

	case PPK2_CMD_GET_METADATA:
		handle_get_metadata();
		break;

	case PPK2_CMD_SET_USER_GAINS:
		handle_set_user_gains(c->arg);
		break;

	case PPK2_CMD_RESET:
		stream_stop();
		power_set_output(false);
		k_sleep(K_MSEC(100));
		sys_reboot(SYS_REBOOT_COLD);
		break;

	default:
		/* PPK1-era commands: accepted for compatibility, no effect. */
		break;
	}
}

static void command_thread(void *p1, void *p2, void *p3)
{
	struct cmd c;

	ARG_UNUSED(p1);
	ARG_UNUSED(p2);
	ARG_UNUSED(p3);

	for (;;) {
		if (k_msgq_get(&cmd_q, &c, K_FOREVER) == 0) {
			dispatch(&c);
		}
	}
}

/*
 * Moves complete blocks from the sample ring to USB. After a stop it also
 * flushes whatever partial block is left so the host sees every sample taken.
 */
static void pump_thread(void *p1, void *p2, void *p3)
{
	static uint32_t block[PPK2_BLOCK_SAMPLES * PPK2_WORDS_PER_SAMPLE];

	ARG_UNUSED(p1);
	ARG_UNUSED(p2);
	ARG_UNUSED(p3);

	for (;;) {
		sampling_wait_block(K_MSEC(200));

		for (;;) {
			size_t avail = sampling_available();
			bool running = sampling_running();

			if (avail == 0 || (avail < PPK2_BLOCK_SAMPLES && running)) {
				break;
			}

			size_t n = sampling_take(block, MIN(avail, PPK2_BLOCK_SAMPLES));

			if (n == 0) {
				break;
			}

			if (!streaming) {
				continue;
			}

			k_mutex_lock(&tx_lock, K_FOREVER);
			int ret = usb_ppk_data_send((const uint8_t *)block,
						    n * PPK2_WORDS_PER_SAMPLE * sizeof(uint32_t),
						    TX_BLOCK_TIMEOUT);

			k_mutex_unlock(&tx_lock);

			if (ret == 0) {
				sampling_count_block_sent();
			} else {
				stats.tx_failures++;
			}
		}
	}
}

K_THREAD_DEFINE(protocol_cmd_tid, 2048, command_thread, NULL, NULL, NULL,
		K_PRIO_PREEMPT(6), 0, 0);
K_THREAD_DEFINE(protocol_pump_tid, 2048, pump_thread, NULL, NULL, NULL,
		K_PRIO_PREEMPT(2), 0, 0);

int protocol_init(void)
{
	usb_ppk_set_callbacks(rx_handler, link_handler);
	return 0;
}

bool protocol_streaming(void)
{
	return streaming;
}

void protocol_get_stats(struct protocol_stats *st)
{
	*st = stats;
}
```

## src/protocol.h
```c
/*
 * PPK2 host protocol on the USB data port.
 *
 * SPDX-License-Identifier: Apache-2.0
 */

#ifndef PROTOCOL_H_
#define PROTOCOL_H_

#include <stdbool.h>
#include <stdint.h>

struct protocol_stats {
	uint32_t commands;
	uint32_t unknown_bytes;
	uint32_t tx_failures;
};

int protocol_init(void);

bool protocol_streaming(void);
void protocol_get_stats(struct protocol_stats *st);

#endif /* PROTOCOL_H_ */
```

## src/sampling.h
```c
/*
 * SAADC front end: the current + DUT-voltage stream and the slow monitors.
 *
 * SPDX-License-Identifier: Apache-2.0
 */

#ifndef SAMPLING_H_
#define SAMPLING_H_

#include <stdbool.h>
#include <stddef.h>
#include <stdint.h>
#include <zephyr/kernel.h>

/* END-to-handler latency histogram, 1 us per bucket, last bucket open-ended. */
#define SAMPLING_LATENCY_BUCKETS	24

struct sampling_metrics {
	uint32_t samples_emitted;
	uint32_t switch_dropped;
	uint32_t blocks_dropped;
	uint32_t blocks_sent;
	/* SAADC END events counted in hardware (TIMER3) since the last start. */
	uint32_t end_events;
	/* Times the END interrupt actually ran. Fewer than end_events means
	 * conversions were lost to interrupt latency.
	 */
	uint32_t isr_entries;
	/* END events that passed between consecutive ISR entries without one
	 * of their own, and the largest such run.
	 */
	uint32_t isr_missed_ends;
	uint32_t isr_max_end_gap;
	/* Longest handler run seen, in 16 MHz ticks (160 per sample). */
	uint32_t isr_max_run_ticks;
	/* END event to handler entry, 16 MHz ticks, and its distribution. */
	uint32_t isr_max_latency_ticks;
	uint32_t isr_latency_hist[SAMPLING_LATENCY_BUCKETS];
};

/* Runs the sampler with nothing consuming the stream, then reports metrics.
 * With spin set the calling thread busy-waits instead of sleeping, which
 * keeps the CPU out of WFI for the duration. period is the sample period in
 * 16 MHz ticks (160 for the production rate).
 */
int sampling_selftest(uint32_t seconds, bool spin, uint32_t period, struct sampling_metrics *m);

enum sampling_channel {
	SAMPLING_CH_VSE_IA,	/* AIN7, instrumentation amplifier output */
	SAMPLING_CH_VREF_IA,	/* AIN0, instrumentation amplifier reference */
	SAMPLING_CH_VLDO,	/* AIN1, LDO output, /5 */
	SAMPLING_CH_VBB,	/* AIN2, buck-boost output, /5 */
	SAMPLING_CH_VIN,	/* AIN3, VIN terminal, /5 */
	SAMPLING_CH_VDUT,	/* AIN4, VDUT+, /5 */
	SAMPLING_CH_NTC,	/* AIN6, thermistor divider */
	SAMPLING_CH_COUNT,
};

int sampling_init(void);

int sampling_start(void);
void sampling_stop(void);
bool sampling_running(void);

/* Blocks until a block-sized run of samples is likely available. */
int sampling_wait_block(k_timeout_t timeout);

/* Samples ready to be taken; also recovers from ring overflow. */
size_t sampling_available(void);

/* Copies out up to n samples of PPK2_WORDS_PER_SAMPLE words each; dst must
 * hold n * PPK2_WORDS_PER_SAMPLE words. Returns the number of samples copied.
 */
size_t sampling_take(uint32_t *dst, size_t n);

void sampling_get_metrics(struct sampling_metrics *m);
void sampling_reset_metrics(void);
void sampling_count_block_sent(void);

void sampling_set_discard_switch(bool enable);
bool sampling_get_discard_switch(void);

/* SAADC acquisition-time code for the stream (CONFIG.TACQ, 0..7). Takes
 * effect at the next start. Exposed for experiments; see STREAM_TACQ_CODE.
 */
int sampling_set_tacq(uint8_t code);
uint8_t sampling_get_tacq(void);

/* Same, for the voltage channel of the stream. */
int sampling_set_tacq_v(uint8_t code);
uint8_t sampling_get_tacq_v(void);

/*
 * One 256x oversampled conversion. Only while the stream is stopped.
 * The result is the voltage at the measured node, dividers included.
 */
int sampling_measure_mv(enum sampling_channel ch, float *mv);

/* Averaged raw 14-bit differential reading, for calibration work. */
int sampling_measure_raw(enum sampling_channel ch, unsigned int count, int32_t *raw_avg);

/* The stream's voltage word scale: mV = raw * full_scale_mv / 8192 * divider. */
void sampling_voltage_scale(float *full_scale_mv, float *divider);

#endif /* SAMPLING_H_ */
```
